# RA register map
Vendor: Renesas; Series: All Chips; File version: x.xx
Registers are 32-bit, read-write, reset 0x0 unless marked. A register's access mark holds for its fields unless they carry their own. Offsets are from the block's base; [hi:lo] are bit positions; {n}, {i} and the like mark numbered series; 'fields as' and 'values as' point back to an identical list.

## R_SCI0 — Serial Communications Interface
Base 0x40118000
Same registers: R_SCI{n} {0x40118000+0x100*n} (n=1..9)
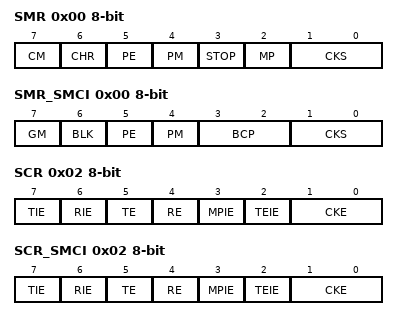
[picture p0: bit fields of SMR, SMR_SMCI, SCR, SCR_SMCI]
0x00 SMR 8-bit — Serial Mode Register (SCMR.SMIF = 0)
  [7] CM — Communication Mode
    0=Asynchronous mode or simple I2C mode; 1=Clock synchronous mode
  [6] CHR — Character Length(Valid only in asynchronous mode)
    0=Transmit/receive in 9-bit data length(SCMR.CHR1=0) / in 8bit data length(SCMR.CHR1=1); 1=Transmit/receive in 9-bit data length(SCMR.CHR1=0) / in 7bit data length(SCMR.CHR1=1)
  [5] PE — Parity Enable(Valid only in asynchronous mode)
    0=Parity bit addition is not performed (transmitting) / Parity bit checking is not performed ( receiving ); 1=The parity bit is added (transmitting) / The parity bit is checked (receiving)
  [4] PM — Parity Mode (Valid only when the PE bit is 1)
    0=Selects even parity; 1=Selects odd parity
  [3] STOP — Stop Bit Length(Valid only in asynchronous mode)
    0=1 stop bit; 1=2 stop bits
  [2] MP — Multi-Processor Mode(Valid only in asynchronous mode)
    0=Multi-processor communications function is disabled; 1=Multi-processor communications function is enabled
  [1:0] CKS — Clock Select
    0=PCLK clock; 1=PCLK/4 clock; 2=PCLK/16 clock; 3=PCLK/64 clock
0x00 SMR_SMCI 8-bit (alternate view of SMR) — Serial mode register (SCMR.SMIF = 1)
  [7] GM — GSM Mode
    0=Normal mode operation; 1=GSM mode operation
  [6] BLK — Block Transfer Mode
    0=Normal mode operation; 1=Block transfer mode operation
  [5] PE — Parity Enable(Valid only in asynchronous mode)
    0=Setting Prohibited; 1=Set this bit to 1 in smart card interface mode
  [4] PM — Parity Mode (Valid only when the PE bit is 1)
    0=Selects even parity; 1=Selects odd parity
  [3:2] BCP — Base Clock Pulse(Valid only in asynchronous mode)
    0=93 clock cycles(S=93) (SCMR.BCP2=0) / 32 clock cycles(S=32) (SCMR.BCP2=1); 1=128 clock cycles(S=128) (SCMR.BCP2=0) / 64 clock cycles(S=64) (SCMR.BCP2=1); 2=186 clock cycles(S=186) (SCMR.BCP2=0) / 372 clock cycles(S=372) (SCMR.BCP2=1); 3=512 clock cycles(S=512) (SCMR.BCP2=0) / 256 clock cycles(S=256) (SCMR.BCP2=1)
  [1:0] CKS — Clock Select
    values as SMR.CKS
0x01 BRR 8-bit reset 0xFF — Bit Rate Register
  [7:0] BRR — BRR is an 8-bit register that adjusts the bit rate.
0x02 SCR 8-bit — Serial Control Register (SCMR.SMIF = 0)
  [7] TIE — Transmit Interrupt Enable
    0=SCI_TXI interrupt request is disabled; 1=SCI_TXI interrupt request is enabled
  [6] RIE — Receive Interrupt Enable
    0=SCI_RXI and SCI_ERI interrupt requests are disabled; 1=SCI_RXI and SCI_ERI interrupt requests are enabled
  [5] TE — Transmit Enable
    0=Serial transmission is disabled; 1=Serial transmission is enabled
  [4] RE — Receive Enable
    0=Serial reception is disabled; 1=Serial reception is enabled
  [3] MPIE — Multi-Processor Interrupt Enable(Valid in asynchronous mode when SMR.MP = 1)
    0=Normal reception; 1=When the data with the multi-processor bit set to 0 is received, the data is not read, and setting the status flags RDRF,ORER and FER in SSR to 1 is disabled. When the data with the multiprocessor bit set to 1 is received, the MPIE bit is automatically cleared to 0, and normal reception is resumed.
  [2] TEIE — Transmit End Interrupt Enable
    0=SCI_TEI interrupt request is disabled; 1=SCI_TEI interrupt request is enabled
  [1:0] CKE — Clock Enable
    0=The SCKn pin is available for use as an I/O port in accord with the I/O port settings.(Asynchronous mode) / The SCKn pin functions as the clock output pin(Clock synchronous mode); 1=The clock with the same frequency as the bit rate is output from the SCKn pin.(Asynchronous mode) / The SCKn pin functions as the clock output pin(Clock synchronous mode); other=others (The clock with a frequency 16 times the bit rate should be input from the SCKn pin. (when SEMR.ABCS bit is 0) Input a clock signal with a frequency 8 times the bit rate when the SEMR.ABCS bit is 1.(Asynchronous mode) / The SCKn pin functions as the clock input pin(Clock synchronous mode))
0x02 SCR_SMCI 8-bit (alternate view of SCR) — Serial Control Register (SCMR.SMIF =1)
  [7] TIE — Transmit Interrupt Enable
    0=A SCI_TXI interrupt request is disabled; 1=A SCI_TXI interrupt request is enabled
  [6] RIE — Receive Interrupt Enable
    values as SCR.RIE
  [5] TE — Transmit Enable
    values as SCR.TE
  [4] RE — Receive Enable
    values as SCR.RE
  [3] MPIE — Multi-Processor Interrupt Enable
  [2] TEIE — Transmit End Interrupt Enable
  [1:0] CKE — Clock Enable
    0=Output disabled(SMR_SMCI.GM=0) / Output fixed low(SMR_SMCI.GM=1); 1=Clock Output; 2=Setting prohibited(SMR_SMCI.GM=0) / Output fixed High(SMR_SMCI.GM=1); 3=Setting prohibited(SMR_SMCI.GM=0) / Clock Output(SMR_SMCI.GM=1)
0x03 TDR 8-bit reset 0xFF — Transmit Data Register
  [7:0] TDR — TDR is an 8-bit register that stores transmit data.
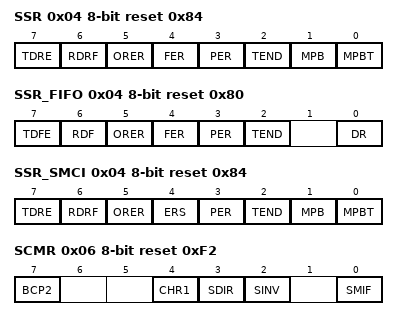
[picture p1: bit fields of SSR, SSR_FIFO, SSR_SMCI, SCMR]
0x04 SSR 8-bit reset 0x84 — Serial Status Register(SCMR.SMIF = 0 and FCR.FM=0)
  [7] TDRE write-0-clears read-modifies — Transmit Data Empty Flag
    0=Transmit data is in TDR register; 1=No transmit data is in TDR register
  [6] RDRF write-0-clears read-modifies — Receive Data Full Flag
    0=No received data is in RDR register; 1=Received data is in RDR register
  [5] ORER write-0-clears read-modifies — Overrun Error Flag
    0=No overrun error occurred; 1=An overrun error has occurred
  [4] FER write-0-clears read-modifies — Framing Error Flag
    0=No framing error occurred; 1=A framing error has occurred
  [3] PER write-0-clears read-modifies — Parity Error Flag
    0=No parity error occurred; 1=A parity error has occurred
  [2] TEND ro — Transmit End Flag
    0=A character is being transmitted; 1=Character transfer has been completed
  [1] MPB ro — Multi-Processor
    0=Data transmission cycles; 1=ID transmission cycles
  [0] MPBT — Multi-Processor Bit Transfer
    0=Data transmission cycles; 1=ID transmission cycles
0x04 SSR_FIFO 8-bit reset 0x80 (alternate view of SSR) — Serial Status Register(SCMR.SMIF = 0 and FCR.FM=1)
  [7] TDFE write-0-clears read-modifies — Transmit FIFO data empty flag
    0=The quantity of transmit data written in FTDR exceeds the specified transmit triggering number; 1=The quantity of transmit data written in FTDR is equal to or less than the specified transmit triggering number
  [6] RDF write-0-clears read-modifies — Receive FIFO data full flag
    0=The quantity of receive data written in FRDR falls below the specified receive triggering number; 1=The quantity of receive data written in FRDR is equal to or greater than the specified receive triggering number
  [5] ORER write-0-clears read-modifies — Overrun Error Flag
    0=No overrun error occurred; 1=An overrun error has occurred
  [4] FER write-0-clears read-modifies — Framing Error Flag
    0=No framing error occurred; 1=A framing error has occurred
  [3] PER write-0-clears read-modifies — Parity Error Flag
    0=No parity error occurred; 1=A parity error has occurred
  [2] TEND write-0-clears read-modifies — Transmit End Flag
    0=A character is being transmitted or standing by for transmission; 1=Character transfer has been completed
  [0] DR write-0-clears read-modifies — Receive Data Ready flag(Valid only in asynchronous mode(including multi-processor) and FIFO selected)
    0=Receiving is in progress, or no received data has remained in FRDR after normally completed receiving.(receive FIFO is empty); 1=Next receive data has not been received for a period after normal completed receiving, , when data is stored in FIFO to equal or less than receive triggering number
0x04 SSR_SMCI 8-bit reset 0x84 (alternate view of SSR) — Serial Status Register(SCMR.SMIF = 1)
  [7] TDRE write-0-clears read-modifies — Transmit Data Empty Flag
    values as SSR.TDRE
  [6] RDRF write-0-clears read-modifies — Receive Data Full Flag
    values as SSR.RDRF
  [5] ORER write-0-clears read-modifies — Overrun Error Flag
    0=No overrun error occurred; 1=An overrun error has occurred
  [4] ERS write-0-clears read-modifies — Error Signal Status Flag
    0=Low error signal not responded; 1=Low error signal responded
  [3] PER write-0-clears read-modifies — Parity Error Flag
    0=No parity error occurred; 1=A parity error has occurred
  [2] TEND ro — Transmit End Flag
    values as SSR.TEND
  [1] MPB ro — Multi-ProcessorThis bit should be 0 in smart card interface mode.
  [0] MPBT — Multi-Processor Bit TransferThis bit should be 0 in smart card interface mode.
0x05 RDR 8-bit ro — Receive Data Register
  [7:0] RDR — RDR is an 8-bit register that stores receive data.
0x06 SCMR 8-bit reset 0xF2 — Smart Card Mode Register
  [7] BCP2 — Base Clock Pulse 2Selects the number of base clock cycles in combination with the SMR.BCP[1:0] bits
    0=S=93(SMR.BCP[1:0]=00), 128(SMR.BCP[1:0]=01), 186(SMR.BCP[1:0]=10), 512(SMR.BCP[1:0]=11); 1=S=32(SMR.BCP[1:0]=00), 64(SMR.BCP[1:0]=01), 372(SMR.BCP[1:0]=10), 256(SMR.BCP[1:0]=11)
  [4] CHR1 — Character Length 1(Only valid in asynchronous mode)
    0=Transmit/receive in 9-bit data length; 1=Transmit/receive in 8-bit data length(SMR.CHR=0) / in 7bit data length(SMR.CHR=1)
  [3] SDIR — Transmitted/Received Data Transfer DirectionNOTE: The setting is invalid and a fixed data length of 8 bits is used in modes other than asynchronous mode.Set this bit to 1 if operation is to be in simple I2C mode.
    0=Transfer with LSB first; 1=Transfer with MSB first
  [2] SINV — Transmitted/Received Data InvertSet this bit to 0 if operation is to be in simple I2C mode.
    0=TDR contents are transmitted as they are. Receive data is stored as it is in RDR.; 1=TDR contents are inverted before being transmitted. Receive data is stored in inverted form in RDR.
  [0] SMIF — Smart Card Interface Mode Select
    0=Non-smart card interface mode(Asynchronous mode, clock synchronous mode, simple SPI mode, or simple I2C mode); 1=Smart card interface mode
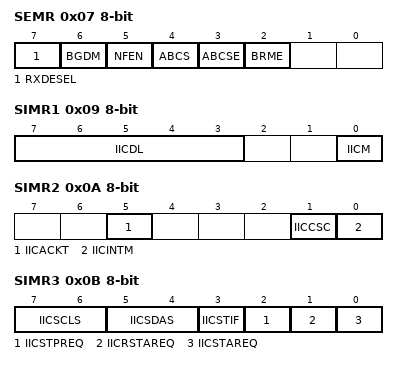
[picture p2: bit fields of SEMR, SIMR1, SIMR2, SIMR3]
0x07 SEMR 8-bit — Serial Extended Mode Register
  [7] RXDESEL — Asynchronous Start Bit Edge Detection Select(Valid only in asynchronous mode)
    0=The low level on the RXDn pin is detected as the start bit; 1=A falling edge on the RXDn pin is detected as the start bit
  [6] BGDM — Baud Rate Generator Double-Speed Mode Select(Only valid the CKE[1] bit in SCR is 0 in asynchronous mode).
    0=Baud rate generator outputs the clock with normal frequency; 1=Baud rate generator outputs the clock with doubled frequency
  [5] NFEN — Digital Noise Filter Function Enable(The NFEN bit should be 0 without simple I2C mode and asynchronous mode.)In asynchronous mode, for RXDn input only. In simple I2C mode, for RXDn/TxDn input.
    0=Noise cancellation function for the RXDn/SSCLn and SSDAn input signal is disabled; 1=Noise cancellation function for the RXDn/SSCLn and SSDAn input signal is enabled
  [4] ABCS — Asynchronous Mode Base Clock Select(Valid only in asynchronous mode)
    0=Selects 16 base clock cycles for 1-bit period; 1=Selects 8 base clock cycles for 1-bit period
  [3] ABCSE — Asynchronous Mode Extended Base Clock Select 1(Valid only in asynchronous mode and SCR.CKE[1]=0)
    0=Clock cycles for 1-bit period is decided with combination between BGDM and ABCS in SEMR; 1=Baud rate is 6 base clock cycles for 1-bit period and the clock of a double frequency is output from the baud rate generator
  [2] BRME — Bit Rate Modulation Enable
    0=Bit rate modulation function is disabled; 1=Bit rate modulation function is enabled
0x08 SNFR 8-bit — Noise Filter Setting Register
  [2:0] NFCS — Noise Filter Clock Select
    0=The clock signal divided by 1 is used with the noise filter.(In asynchronous mode); 1=The clock signal divided by 1 is used with the noise filter.(In simple I2C mode); 2=The clock signal divided by 2 is used with the noise filter.(In simple I2C mode); 3=The clock signal divided by 4 is used with the noise filter.(In simple I2C mode); 4=The clock signal divided by 8 is used with the noise filter.(In simple I2C mode); other=others (Settings prohibited.)
0x09 SIMR1 8-bit — I2C Mode Register 1
  [7:3] IICDL — SDA Delay Output SelectCycles below are of the clock signal from the on-chip baud rate generator.
    0=No output delay; other=others ((IICDL - 1 ) to IIDCDL cycles. The delay is in the clock cycles from the on-chip baud rate generator.)
  [0] IICM — Simple I2C Mode Select
    0=Asynchronous mode, Multi-processor mode, Clock synchronous mode(SCMR.SMIF=0) /Smart card interface mode(SCMR.SMIF=1); 1=Simple I2C mode(SCMR.SMIF=0) / Setting prohibited.(SCMR.SMIF=1)
0x0A SIMR2 8-bit — I2C Mode Register 2
  [5] IICACKT — ACK Transmission Data
    0=ACK transmission; 1=NACK transmission and reception of ACK/NACK
  [1] IICCSC — Clock Synchronization
    0=No synchronization with the clock signal; 1=Synchronization with the clock signal
  [0] IICINTM — I2C Interrupt Mode Select
    0=Use ACK/NACK interrupts; 1=Use reception and transmission interrupts
0x0B SIMR3 8-bit — I2C Mode Register 3
  [7:6] IICSCLS — SCL Output Select
    0=Serial clock output; 1=Generate a start, restart, or stop condition; 2=Output the low level on the SSCLn pin; 3=Place the SSCLn pin in the high-impedance state
  [5:4] IICSDAS — SDA Output Select
    0=Serial data output; 1=Generate a start, restart, or stop condition; 2=Output the low level on the SSDAn pin; 3=Place the SSDAn pin in the high-impedance state
  [3] IICSTIF write-0-clears read-modifies — Issuing of Start, Restart, or Stop Condition Completed Flag(When 0 is written to IICSTIF, it is cleared to 0.)
    0=There are no requests for generating conditions or a condition is being generated; 1=A start, restart, or stop condition is completely generated
  [2] IICSTPREQ — Stop Condition Generation
    0=A stop condition is not generated; 1=A stop condition is generated
  [1] IICRSTAREQ — Restart Condition Generation
    0=A restart condition is not generated; 1=A restart condition is generated
  [0] IICSTAREQ — Start Condition Generation
    0=A start condition is not generated; 1=A start condition is generated
0x0C SISR 8-bit ro — I2C Status Register
  [0] IICACKR — ACK Reception Data Flag
    0=ACK received; 1=NACK received
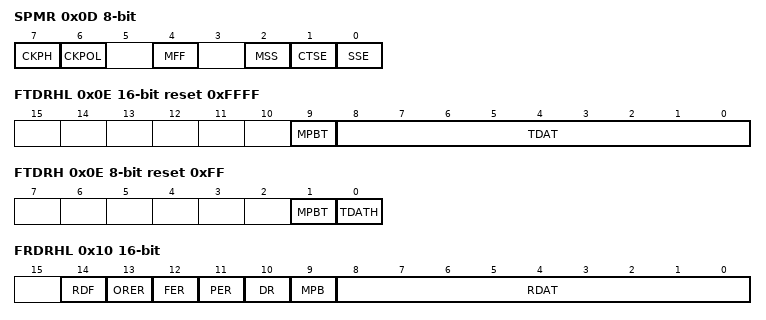
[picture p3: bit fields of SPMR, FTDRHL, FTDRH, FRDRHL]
0x0D SPMR 8-bit — SPI Mode Register
  [7] CKPH — Clock Phase Select
    0=Clock is not delayed; 1=Clock is delayed
  [6] CKPOL — Clock Polarity Select
    0=Clock polarity is not inverted; 1=Clock polarity is inverted
  [4] MFF write-0-clears read-modifies — Mode Fault Flag
    0=No mode fault error; 1=Mode fault error
  [2] MSS — Master Slave Select
    0=Transmission is through the TXDn pin and reception is through the RXDn pin (master mode); 1=Reception is through the TXDn pin and transmission is through the RXDn pin (slave mode)
  [1] CTSE — CTS Enable
    0=CTS function is disabled (RTS output function is enabled); 1=CTS function is enabled
  [0] SSE — SSn Pin Function Enable
    0=SSn pin function is disabled; 1=SSn pin function is enabled
0x0E TDRHL 16-bit reset 0xFFFF — Transmit 9-bit Data Register
  [15:0] TDRHL wo — TDRHL is a 16-bit register that stores transmit data.
0x0E FTDRHL 16-bit wo reset 0xFFFF (alternate view of TDRHL) — Transmit FIFO Data Register HL
  [9] MPBT — Multi-processor transfer bit flag(Valid only in asynchronous mode and SMR.MP=1 and FIFO selected)
    0=Data transmission cycles; 1=ID transmission cycles
  [8:0] TDAT — Serial transmit data (Valid only in asynchronous mode(including multi-processor) or clock synchronous mode, and FIFO selected)
0x0E FTDRH 8-bit wo reset 0xFF (alternate view of TDRHL) — Transmit FIFO Data Register H
  [1] MPBT — Multi-processor transfer bit flag(Valid only in asynchronous mode and SMR.MP=1 and FIFO selected)
    0=Data transmission cycles; 1=ID transmission cycles
  [0] TDATH — Serial transmit data (b8) (Valid only in asynchronous mode(including multi-processor) or clock synchronous mode, and FIFO selected)
0x0F FTDRL 8-bit wo reset 0xFF (alternate view of TDRHL) — Transmit FIFO Data Register L
  [7:0] TDATL — Serial transmit data(b7-b0) (Valid only in asynchronous mode(including multi-processor) or clock synchronous mode, and FIFO selected)
0x10 RDRHL 16-bit ro — Receive 9-bit Data Register
  [15:0] RDRHL — RDRHL is an 16-bit register that stores receive data.
0x10 FRDRHL 16-bit ro (alternate view of RDRHL) — Receive FIFO Data Register HL
  [14] RDF — Receive FIFO data full flag(It is same as SSR.RDF)
    0=The quantity of receive data written in FRDRH and FRDRL falls below the specified receive triggering number; 1=The quantity of receive data written in FRDRH and FRDRL is equal to or greater than the specified receive triggering number
  [13] ORER — Overrun error flag(It is same as SSR.ORER)
    0=No overrun error occurred; 1=An overrun error has occurred
  [12] FER — Framing error flag
    0=No framing error occurred at the first data of FRDRH and FRDRL; 1=A framing error has occurred at the first data of FRDRH and FRDRL
  [11] PER — Parity error flag
    0=No parity error occurred at the first data of FRDRH and FRDRL; 1=A parity error has occurred at the first data of FRDRH and FRDRL
  [10] DR — Receive data ready flag(It is same as SSR.DR)
    0=Receiving is in progress, or no received data has remained in FRDRH and FRDRL after normally completed receiving; 1=Next receive data has not been received for a period after normal completed receiving
  [9] MPB — Multi-processor bit flag(Valid only in asynchronous mode with SMR.MP=1 and FIFO selected) It can read multi-processor bit corresponded to serial receive data(RDATA[8:0])
    0=Data transmission cycles; 1=ID transmission cycles
  [8:0] RDAT — Serial receive data(Valid only in asynchronous mode(including multi-processor) or clock synchronous mode, and FIFO selected)
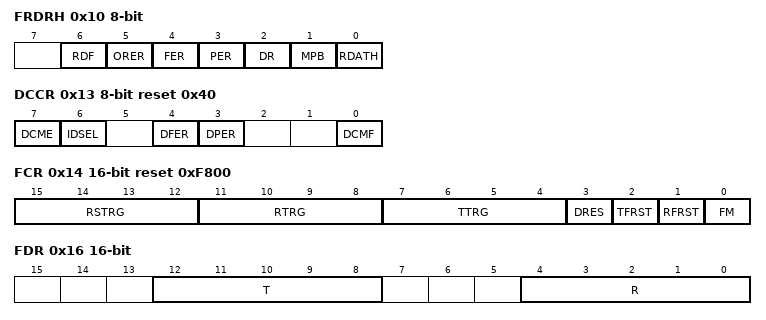
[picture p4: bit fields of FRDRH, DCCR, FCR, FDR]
0x10 FRDRH 8-bit ro (alternate view of RDRHL) — Receive FIFO Data Register H
  [6] RDF — Receive FIFO data full flag(It is same as SSR.RDF)
    values as FRDRHL.RDF
  [5] ORER — Overrun error flag(It is same as SSR.ORER)
    0=No overrun error occurred; 1=An overrun error has occurred
  [4] FER — Framing error flag
    values as FRDRHL.FER
  [3] PER — Parity error flag
    values as FRDRHL.PER
  [2] DR — Receive data ready flag(It is same as SSR.DR)
    values as FRDRHL.DR
  [1] MPB — Multi-processor bit flag(Valid only in asynchronous mode with SMR.MP=1 and FIFO selected) It can read multi-processor bit corresponded to serial receive data(RDATA[8:0])
    0=Data transmission cycles; 1=ID transmission cycles
  [0] RDATH — Serial receive data(b8)(Valid only in asynchronous mode(including multi-processor) or clock synchronous mode, and FIFO selected)
0x11 FRDRL 8-bit ro (alternate view of RDRHL) — Receive FIFO Data Register L
  [7:0] RDATL — Serial receive data(Valid only in asynchronous mode(including multi-processor) or clock synchronous mode, and FIFO selected)NOTE: When reading both of FRDRH register and FRDRL register, please read by an order of the FRDRH register and the FRDRL register.
0x12 MDDR 8-bit reset 0xFF — Modulation Duty Register
  [7:0] MDDR — MDDR corrects the bit rate adjusted by the BRR register.
0x13 DCCR 8-bit reset 0x40 — Data Compare Match Control Register
  [7] DCME — Data Compare Match Enable(Valid only in asynchronous mode(including multi-processor)
    0=Address match function is disabled; 1=Address match function is enabled
  [6] IDSEL — ID frame select(Valid only in asynchronous mode(including multi-processor)
    0=Always compare data regardless of the value of the MPB bit; 1=Compare data when the MPB bit is 1 (ID frame) only
  [4] DFER write-0-clears read-modifies — Data Compare Match Framing Error Flag
    0=No framing error occurred; 1=A framing error has occurred
  [3] DPER write-0-clears read-modifies — Data Compare Match Parity Error Flag
    0=No parity error occurred; 1=A parity error has occurred
  [0] DCMF write-0-clears read-modifies — Data Compare Match Flag
    0=No matched; 1=Matched
0x14 FCR 16-bit reset 0xF800 — FIFO Control Register
  [15:12] RSTRG — RTS Output Active Trigger Number Select(Valid only in asynchronous mode(including multi-processor) or clock synchronous mode)
    0=Trigger number 0; other=others (Triger number n (n= 0-15))
  [11:8] RTRG — Receive FIFO data trigger number(Valid only in asynchronous mode(including multi-processor) or clock synchronous mode)
    0=Trigger number 0; other=others (Triger number n (n= 0-15))
  [7:4] TTRG — Transmit FIFO data trigger number(Valid only in asynchronous mode(including multi-processor) or clock synchronous mode)
    0=Trigger number 0; other=others (Triger number n (n= 0-15))
  [3] DRES — Receive data ready error select bit(When detecting a reception data ready, the interrupt request is selected.)
    0=reception data full interrupt (RXI); 1=receive error interrupt (ERI)
  [2] TFRST — Transmit FIFO Data Register Reset(Valid only in FCR.FM=1)
    0=The number of data stored in FTDRH and FTDRL register are NOT made 0; 1=The number of data stored in FTDRH and FTDRL register are made 0
  [1] RFRST — Receive FIFO Data Register Reset(Valid only in FCR.FM=1)
    0=The number of data stored in FRDRH and FRDRL register are NOT made 0; 1=The number of data stored in FRDRH and FRDRL register are made 0
  [0] FM — FIFO Mode Select(Valid only in asynchronous mode(including multi-processor) or clock synchronous mode)
    0=Non-FIFO mode(Selects o TDR/RDR for communication); 1=FIFO mode (Selects to FTDRH and FTDRL/FRDRH and FRDRL for communication)
0x16 FDR 16-bit ro — FIFO Data Count Register
  [12:8] T — Transmit FIFO Data CountIndicate the quantity of non-transmit data stored in FTDRH and FTDRL(Valid only in asynchronous mode(including multi-processor) or clock synchronous mode, while FCR.FM=1)
  [4:0] R — Receive FIFO Data CountIndicate the quantity of receive data stored in FRDRH and FRDRL(Valid only in asynchronous mode(including multi-processor) or clock synchronous mode, while FCR.FM=1)
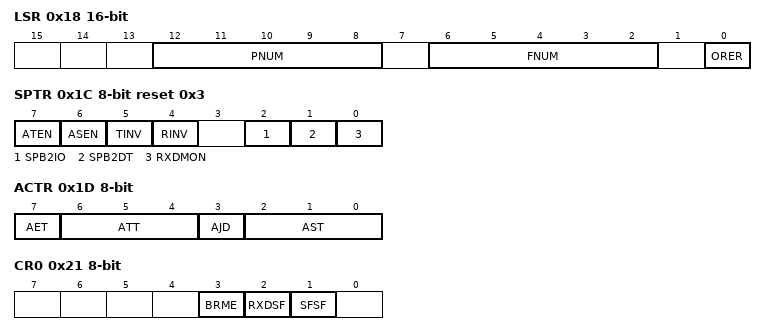
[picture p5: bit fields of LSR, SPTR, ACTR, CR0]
0x18 LSR 16-bit ro — Line Status Register
  [12:8] PNUM — Parity Error CountIndicates the quantity of data with a parity error among the receive data stored in the receive FIFO data register (FRDRH and FRDRL).
  [6:2] FNUM — Framing Error CountIndicates the quantity of data with a framing error among the receive data stored in the receive FIFO data register (FRDRH and FRDRL).
  [0] ORER — Overrun Error Flag (Valid only in asynchronous mode(including multi-processor) or clock synchronous mode, and FIFO selected)
    0=No overrun error occurred; 1=An overrun error has occurred
0x1A CDR 16-bit — Compare Match Data Register
  [8:0] CMPD — Compare Match DataCompare data pattern for address match wake-up function
0x1C SPTR 8-bit reset 0x3 — Serial Port Register
  [7] ATEN — Adjust transmit timing enable
    0=Adjust transmit timing disable; 1=Adjust transmit timing enable
  [6] ASEN — Adjust receive sampling timing enable
    0=Adjust sampling timing disable; 1=Adjust sampling timing enable
  [5] TINV — TXD invert bit
    0=Transmit data is not inverted and output to TXD; 1=Transmit data is inverted and output to TXD
  [4] RINV — RXD invert bit
    0=Received data from RXD is not inverted and input; 1=Received data from RXD is inverted and input
  [2] SPB2IO — Serial port break I/O bit(It's selected whether the value of SPB2DT is output to TxD terminal.)
    0=The value of SPB2DT bit is not output in TXD pin; 1=The value of SPB2DT bit is output in TXD pin
  [1] SPB2DT — Serial port break data select bit(The output level of TxD terminal is selected when SCR.TE = 0.)
    0=Low level is output on TXD pin; 1=High level is output on TXD pin
  [0] RXDMON ro — Serial input data monitor bit(The state of the RXD terminal is shown.)
    0=RXD pin is low; 1=RXD pin is high
0x1D ACTR 8-bit — Adjustment Communication Timing Register
  [7] AET — Adjustment edge for transmit timing
    0=Adjust the rising edge timing; 1=Adjust the falling edge timing
  [6:4] ATT — Adjustment value for Transmit timing
  [3] AJD — Adjustment Direction for receive sampling timing
    0=The sampling timing is adjusted backward to the middle of bit; 1=The sampling timing is adjusted forward to the middle of bit
  [2:0] AST — Adjustment value for receive Sampling Timing
0x20 ESMER 8-bit — Extended Serial Module Enable Register
  [0] ESME — Extended Serial Mode Enable
    0=The extended serial mode is disabled; 1=The extended serial mode is enabled
0x21 CR0 8-bit — Control Register 0
  [3] BRME — Bit Rate Measurement Enable
    0=Measurement of bit rate is disabled; 1=Measurement of bit rate is enabled
  [2] RXDSF ro — RXDXn Input Status Flag
    0=RXDXn input is enabled; 1=RXDXn input is disabled
  [1] SFSF ro — Start Frame Status Flag
    0=Start Frame detection function is disabled; 1=Start Frame detection function is enabled
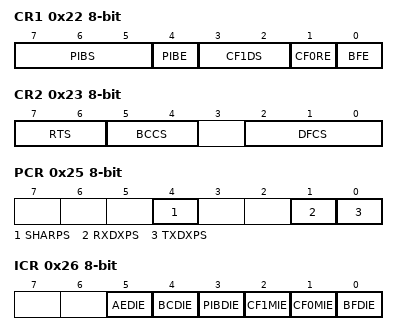
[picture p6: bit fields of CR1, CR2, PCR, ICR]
0x22 CR1 8-bit — Control Register 1
  [7:5] PIBS — Priority Interrupt Bit Select
    0=0th bit of Control Field 1; 1=1st bit of Control Field 1; 2=2nd bit of Control Field 1; 3=3rd bit of Control Field 1; {v}={v}th bit of Control Field 1 (v=4..7)
  [4] PIBE — Priority Interrupt Bit Enable
    0=The priority interrupt bit is disabled; 1=The priority interrupt bit is enabled
  [3:2] CF1DS — Control Field 1 Data Register Select
    0=Selects comparison with the value in PCF1DR; 1=Selects comparison with the value in SCF1DR; 2=Selects comparison with the values in PCF1DR and SCF1DR; 3=Setting prohibited
  [1] CF0RE — Control Field 0 Reception Enable
    0=Reception of Control Field 0 is disabled; 1=Reception of Control Field 0 is enabled
  [0] BFE — Break Field Enable
    0=Break Field detection is disabled; 1=Break Field detection is enabled
0x23 CR2 8-bit — Control Register 2
  [7:6] RTS — RXDXn Reception Sampling Timing Select
    0=Rising edge of the 8th cycle of SCI base clock; 1=Rising edge of the 10th cycle of SCI base clock; 2=Rising edge of the 12th cycle of SCI base clock; 3=Rising edge of the 14th cycle of SCI base clock
  [5:4] BCCS — Bus Collision Detection Clock Select
    0=SCI base clock; 1=SCI base clock frequency divided by 2; 2=SCI base clock frequency divided by 4; 3=Setting prohibited
  [2:0] DFCS — RXDXn Signal Digital Filter Clock Select
    0=Filter is disabled; 1=Filter clock is SCI base clock; 2=Filter clock is PCLK/8; 3=Filter clock is PCLK/16; 4=Filter clock is PCLK/32; 5=Filter clock is PCLK/64; 6=Filter clock is PCLK/128; 7=Setting prohibited
0x24 CR3 8-bit — Control Register 3
  [0] SDST — Start Frame Detection Start
    0=Detection of Start Frame is not performed; 1=Detection of Start Frame is performed
0x25 PCR 8-bit — Port Control Register
  [4] SHARPS — TXDXn/RXDXn Pin Multiplexing Select
    0=The TXDXn and RXDXn pins are independent; 1=The TXDXn and RXDXn signals are multiplexed on the same pin
  [1] RXDXPS — RXDXn Signal Polarity Select
    0=The polarity of RXDXn signal is not inverted for input; 1=The polarity of RXDXn signal is inverted for input
  [0] TXDXPS — TXDXn Signal Polarity Select
    0=The polarity of TXDXn signal is not inverted for output; 1=The polarity of TXDXn signal is inverted for output
0x26 ICR 8-bit — Interrupt Control Register
  [5] AEDIE — Valid Edge Detected Interrupt Enable
    0=Interrupts on detection of a valid edge are disabled; 1=Interrupts on detection of a valid edge are enabled
  [4] BCDIE — Bus Collision Detected Interrupt Enable
    0=Interrupts on detection of a bus collision are disabled; 1=Interrupts on detection of a bus collision are enabled
  [3] PIBDIE — Priority Interrupt Bit Detected Interrupt Enable
    0=Interrupts on detection of the priority interrupt bit are disabled; 1=Interrupts on detection of the priority interrupt bit are enabled
  [2] CF1MIE — Control Field 1 Match Detected Interrupt Enable
    0=Interrupts on detection of a match with Control Field 1 are disabled; 1=Interrupts on detection of a match with Control Field 1 are enabled
  [1] CF0MIE — Control Field 0 Match Detected Interrupt Enable
    0=Interrupts on detection of a match with Control Field 0 are disabled; 1=Interrupts on detection of a match with Control Field 0 are enabled
  [0] BFDIE — Break Field Low Width Detected Interrupt Enable
    0=Interrupts on detection of the low width for a Break Field are disabled; 1=Interrupts on detection of the low width for a Break Field are enabled
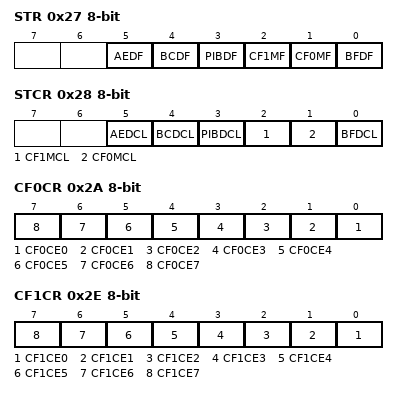
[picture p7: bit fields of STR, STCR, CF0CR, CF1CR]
0x27 STR 8-bit ro — Status Register
  [5] AEDF — Valid Edge Detection Flag
  [4] BCDF — Bus Collision Detected Flag
  [3] PIBDF — Priority Interrupt Bit Detection Flag
  [2] CF1MF — Control Field 1 Match Flag
  [1] CF0MF — Control Field 0 Match Flag
  [0] BFDF — Break Field Low Width Detection Flag
0x28 STCR 8-bit — Status Clear Register
  [5] AEDCL — AEDF Clear
  [4] BCDCL — BCDF Clear
  [3] PIBDCL — PIBDF Clear
  [2] CF1MCL — CF1MF Clear
  [1] CF0MCL — CF0MF Clear
  [0] BFDCL — BFDF Clear
0x29 CF0DR 8-bit — Control Field 0 Data Register
0x2A CF0CR 8-bit — Control Field 0 Compare Enable Register
  [n] CF0CE{n} (n=0..7) — Control Field {n} Bit 0 Compare Enable
    0=Comparison with bit {n} of Control Field 0 is disabled; 1=Comparison with bit {n} of Control Field 0 is enabled
0x2B CF0RR 8-bit — Control Field 0 Receive Data Register
0x2C PCF1DR 8-bit — Primary Control Field 1 Data Register
0x2D SCF1DR 8-bit — Secondary Control Field 1 Data Register
0x2E CF1CR 8-bit — Control Field 1 Compare Enable Register
  [n] CF1CE{n} (n=0..7) — Control Field 1 Bit {n} Compare Enable
    0=Comparison with bit {n} of Control Field 1 is disabled; 1=Comparison with bit {n} of Control Field 1 is enabled
0x2F CF1RR 8-bit — Control Field 1 Receive Data Register
0x30 TCR 8-bit — Timer Control Register
  [0] TCST — Timer Count Start
    0=Stops the timer counting; 1=Starts the timer counting
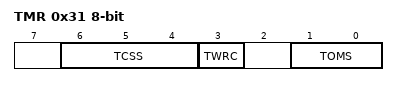
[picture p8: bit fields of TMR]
0x31 TMR 8-bit — Timer Mode Register
  [6:4] TCSS — Timer Count Clock Source Select
    0=PCLK; 1=PCLK/2; 2=PCLK/4; 3=PCLK/8; 4=PCLK/16; 5=PCLK/32; 6=PCLK/64; 7=PCLK/128
  [3] TWRC — Counter Write Control
    0=Data is written to the reload register and counter; 1=Data is written to the reload register only
  [1:0] TOMS — Timer Operating Mode Select
    0=Timer mode; 1=Break Field low width determination mode; 2=Break Field low width output mode; 3=Setting prohibited
0x32 TPRE 8-bit reset 0xFF — Timer Prescaler Register
0x33 TCNT 8-bit reset 0xFF — Timer Count Register
